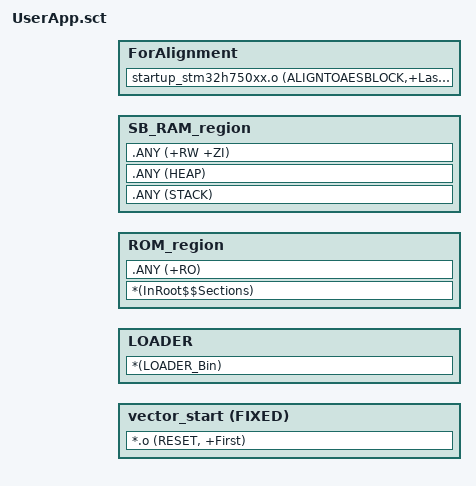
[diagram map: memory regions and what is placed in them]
#! armclang --target=arm-arm-none-eabi  -mcpu=cortex-m7 -E -xc
; *************************************************************
; *** Scatter-Loading Description File generated by uVision ***
; *************************************************************
#include "..\..\Linker_Common\MDK-ARM\mapping_sbsfu.h"
#include "..\..\Linker_Common\MDK-ARM\mapping_fwimg.h"


LR_ROM_1 (SLOT_ACTIVE_1_START + 0x400) {                      ; Cortex-M7: align the init vectors on 0x400
  vector_start (SLOT_ACTIVE_1_START + 0x400) FIXED VECTOR_SIZE {
  *.o (RESET, +First)
  }
}
  
LR_LOADER APP_LOADER_REGION_ROM_START APP_LOADER_ROM_REGION_SIZE {
  LOADER APP_LOADER_REGION_RAM_CODE_START APP_LOADER_RAM_CODE_REGION_SIZE {
  *(LOADER_Bin)
  }
}
  
LR_ROM_2 (APP_LOADER_REGION_ROM_END + 0x1) {
  ROM_region (APP_LOADER_REGION_ROM_END + 0x1) {
  *(InRoot$$Sections)
  .ANY (+RO)
  }

  SB_RAM_region (SE_REGION_RAM_END + 1) {
  .ANY (STACK)
  .ANY (HEAP)
  .ANY (+RW +ZI)
  }
}

; extra ROM region to make sure the binary size is a multiple of the AES block size (16 bytes) and H7 flash writing unit (32 bytes)
LR_ROM1(+0) ALIGN(32) {
  ForAlignment +0 {
    startup_stm32h750xx.o (ALIGNTOAESBLOCK,+Last)
  }
}
